# AS32x601 register map
File version: 1.0
CPU: RISC-V, little endian
Registers are 32-bit, read-write, reset 0x0 unless marked. A register's access mark holds for its fields unless they carry their own. Offsets are from the block's base; [hi:lo] are bit positions.

## USART0 — Universal Synchronous Asynchronous Receiver Transmitter 0
Base 0x50006000
Same registers: USART1 0x50007000, USART2 0x50008000, USART3 0x50009000, USART4 0x51005000, USART5 0x51006000, USART6 0x51007000, USART7 0x51008000
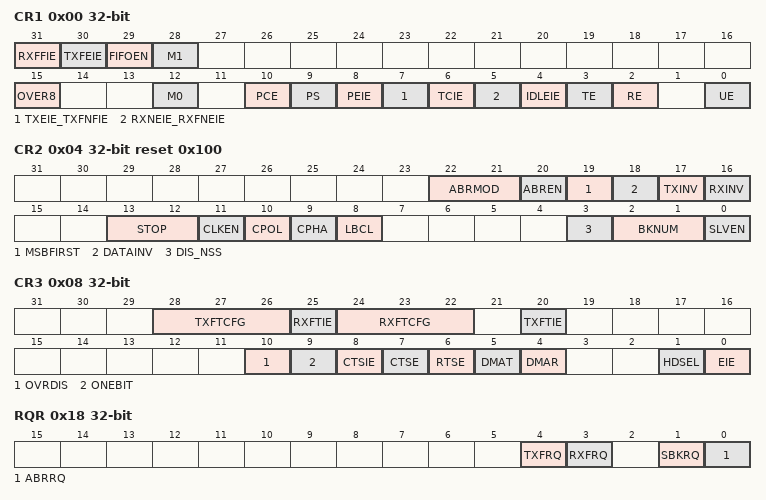
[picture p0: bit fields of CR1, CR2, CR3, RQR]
0x00 CR1 — USART control register 1
  [31] RXFFIE — RXFIFO Full interrupt enable
  [30] TXFEIE — TXFIFO empty interrupt enable
  [29] FIFOEN — FIFO mode enable
  [28] M1 — Word length - Bit 1
  [15] OVER8 — Oversampling by 8-bit or 16-bit mode
  [12] M0 — Word length - Bit 0
  [10] PCE — Parity Control Enable
  [9] PS — Parity Selection
  [8] PEIE — PE Interrupt Enable
  [7] TXEIE_TXFNFIE — TXE and TX FIFO Not Full Interrupt Enable
  [6] TCIE — Transmission Complete Interrupt Enable
  [5] RXNEIE_RXFNEIE — RXNE and RX FIFO Not Empty Interrupt Enable
  [4] IDLEIE — IDLE Interrupt Enable
  [3] TE — Transmitter Enable
  [2] RE — Receiver Enable
  [0] UE — USART Enable
0x04 CR2 reset 0x100 — USART control register 2
  [22:21] ABRMOD — ABRMOD[1:0] bits (Auto Baud-Rate Mode)
  [20] ABREN — Auto Baud-Rate Enable
  [19] MSBFIRST — Most Significant Bit First
  [18] DATAINV — Binary data inversion
  [17] TXINV — TX pin active level inversion
  [16] RXINV — RX pin active level inversion
  [13:12] STOP — STOP[1:0] bits (STOP bits)
  [11] CLKEN — Clock Enable
  [10] CPOL — Clock Polarity
  [9] CPHA — Clock Phase
  [8] LBCL — Last Bit Clock pulse
  [3] DIS_NSS — Negative Slave Select (NSS) pin management
  [2:1] BKNUM — BKNUM[1:0] bits (Send the length of Break characters)
  [0] SLVEN — Synchronous Slave mode Enable
0x08 CR3 — USART control register 3
  [28:26] TXFTCFG — TXFIFO [2:0] threshold configuration
  [25] RXFTIE — RXFIFO threshold interrupt enable
  [24:22] RXFTCFG — RXFTCFG [2:0] Receive FIFO threshold configuration
  [20] TXFTIE — TXFIFO threshold interrupt enable
  [10] OVRDIS — Overrun Disable
  [9] ONEBIT — One sample bit method enable
  [8] CTSIE — CTS Interrupt Enable
  [7] CTSE — CTS Enable
  [6] RTSE — RTS Enable
  [5] DMAT — DMA Enable Transmitter
  [4] DMAR — DMA Enable Receiver
  [1] HDSEL — Half-Duplex Selection
  [0] EIE — Error Interrupt Enable
0x0C BRR — USART baud rate register
  [15:0] DIV — USARTDIV
0x18 RQR wo — USART request register
  [4] TXFRQ — Transmit data flush Request
  [3] RXFRQ — Receive Data flush Request
  [1] SBKRQ — Send Break Request
  [0] ABRRQ — Auto-Baud Rate Request
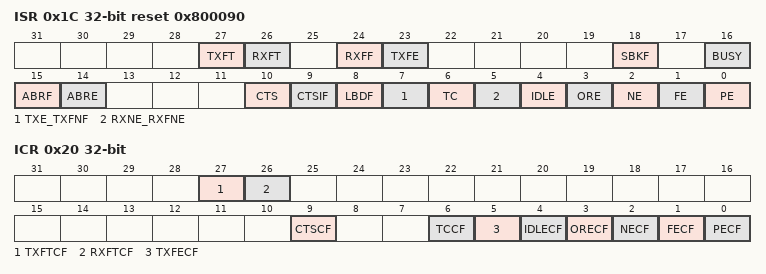
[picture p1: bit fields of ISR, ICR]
0x1C ISR ro reset 0x800090 — USART interrupt and status register
  [27] TXFT — TXFIFO threshold Flag
  [26] RXFT — RXFIFO threshold Flag
  [24] RXFF — RXFIFO Full Flag
  [23] TXFE — TXFIFO Empty
  [18] SBKF — Send Break Flag
  [16] BUSY — Busy Flag
  [15] ABRF — Auto-Baud Rate Flag
  [14] ABRE — Auto-Baud Rate Error
  [10] CTS — CTS flag
  [9] CTSIF — CTS interrupt flag
  [8] LBDF — LIN Break Detection Flag
  [7] TXE_TXFNF — Transmit Data Register Empty or TX FIFO Not Full Flag
  [6] TC — Transmission Complete
  [5] RXNE_RXFNE — Read Data Register or RX FIFO Not Empty
  [4] IDLE — IDLE line detected
  [3] ORE — OverRun Error
  [2] NE — Noise detected Flag
  [1] FE — Framing Error
  [0] PE — Parity Error
0x20 ICR wo — USART interrupt flag clear register
  [27] TXFTCF — Clear TXFIFO threshold interrupt flag
  [26] RXFTCF — Clear RXFIFO threshold interrupt flag
  [9] CTSCF — CTS Interrupt Clear Flag
  [6] TCCF — Transmission Complete Clear Flag
  [5] TXFECF — TXFIFO empty clear flag
  [4] IDLECF — IDLE line detected Clear Flag
  [3] ORECF — OverRun Error Clear Flag
  [2] NECF — Noise detected Clear Flag
  [1] FECF — Framing Error Clear Flag
  [0] PECF — Parity Error Clear Flag
0x24 RDR ro — USART receive data register
  [8:0] RDR — RDR[8:0] bits (Receive Data value)
0x28 TDR wo — USART transmit data register
  [8:0] TDR — TDR[8:0] bits (Transmit Data value)
